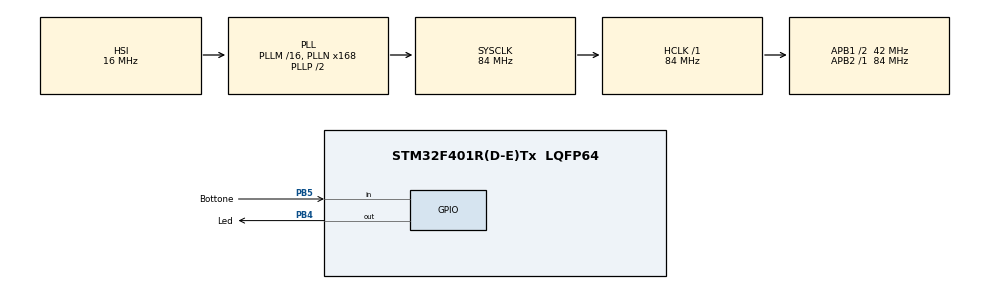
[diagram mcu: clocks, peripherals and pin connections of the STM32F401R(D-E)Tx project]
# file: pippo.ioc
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Mcu.Family=STM32F4
Mcu.Name=STM32F401R(D-E)Tx
Mcu.Package=LQFP64
NVIC.PriorityGroup=NVIC_PRIORITYGROUP_4
PA13.Mode=Serial_Wire
PA13.Signal=SYS_JTMS-SWDIO
PA14.Mode=Serial_Wire
PA14.Signal=SYS_JTCK-SWCLK
PB4.GPIO_Label=Led
PB4.Signal=GPIO_Output
PB5.GPIO_Label=Bottone
PB5.GPIO_PuPd=GPIO_PULLDOWN
PB5.Signal=GPIO_Input
PH0\ -\ OSC_IN.Mode=HSE-External-Oscillator
PH0\ -\ OSC_IN.Signal=RCC_OSC_IN
PH1\ -\ OSC_OUT.Mode=HSE-External-Oscillator
PH1\ -\ OSC_OUT.Signal=RCC_OSC_OUT
ProjectManager.HeapSize=0x200
ProjectManager.StackSize=0x400
ProjectManager.TargetToolchain=MDK-ARM V5.27
RCC.48MHZClocksFreq_Value=42000000
RCC.AHBFreq_Value=84000000
RCC.APB1CLKDivider=RCC_HCLK_DIV2
RCC.APB1Freq_Value=42000000
RCC.APB1TimFreq_Value=84000000
RCC.APB2Freq_Value=84000000
RCC.APB2TimFreq_Value=84000000
RCC.CortexFreq_Value=84000000
RCC.HCLKFreq_Value=84000000
RCC.HSE_VALUE=25000000
RCC.HSI_VALUE=16000000
RCC.LSE_VALUE=32768
RCC.PLLN=168
RCC.SYSCLKFreq_VALUE=84000000
RCC.SYSCLKSource=RCC_SYSCLKSOURCE_PLLCLK
RCC.VCOOutputFreq_Value=168000000
board=custom

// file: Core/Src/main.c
/* USER CODE BEGIN Header */
/**
  ******************************************************************************
  * @file           : main.c
  * @brief          : Main program body
  ******************************************************************************
  * @attention
  *
  * <h2><center>&copy; Copyright (c) 2021 STMicroelectronics.
  * All rights reserved.</center></h2>
  *
  * This software component is licensed by ST under BSD 3-Clause license,
  * the "License"; You may not use this file except in compliance with the
  * License. You may obtain a copy of the License at:
  *                        opensource.org/licenses/BSD-3-Clause
  *
  ******************************************************************************
  */
/* USER CODE END Header */
#include "main.h"

void SystemClock_Config(void);
static void MX_GPIO_Init(void);

int main(void)
{

  /* MCU Configuration--------------------------------------------------------*/

  /* Reset of all peripherals, Initializes the Flash interface and the Systick. */
  HAL_Init();

  /* Configure the system clock */
  SystemClock_Config();

  /* Initialize all configured peripherals */
  MX_GPIO_Init();
  /* USER CODE BEGIN 2 */

	HAL_GPIO_WritePin(Led_GPIO_Port, Led_Pin, GPIO_PIN_RESET);
	Led_GPIO_Port -> ODR &= ~Led_Pin;

	uint8_t stato = 0;

  /* USER CODE END 2 */

  /* Infinite loop */
  /* USER CODE BEGIN WHILE */
  while (1)
  {
		if(HAL_GPIO_ReadPin(Bottone_GPIO_Port, Bottone_Pin)){
				stato = !stato;
				HAL_Delay(250);
		}

	HAL_GPIO_WritePin(Led_GPIO_Port, Led_Pin, stato);
  }
  /* USER CODE END 3 */
}

void SystemClock_Config(void)
{
  RCC_OscInitTypeDef RCC_OscInitStruct = {0};
  RCC_ClkInitTypeDef RCC_ClkInitStruct = {0};

  /** Configure the main internal regulator output voltage
  */
  __HAL_RCC_PWR_CLK_ENABLE();
  __HAL_PWR_VOLTAGESCALING_CONFIG(PWR_REGULATOR_VOLTAGE_SCALE2);
  /** Initializes the RCC Oscillators according to the specified parameters
  * in the RCC_OscInitTypeDef structure.
  */
  RCC_OscInitStruct.OscillatorType = RCC_OSCILLATORTYPE_HSI;
  RCC_OscInitStruct.HSIState = RCC_HSI_ON;
  RCC_OscInitStruct.HSICalibrationValue = RCC_HSICALIBRATION_DEFAULT;
  RCC_OscInitStruct.PLL.PLLState = RCC_PLL_ON;
  RCC_OscInitStruct.PLL.PLLSource = RCC_PLLSOURCE_HSI;
  RCC_OscInitStruct.PLL.PLLM = 16;
  RCC_OscInitStruct.PLL.PLLN = 168;
  RCC_OscInitStruct.PLL.PLLP = RCC_PLLP_DIV2;
  RCC_OscInitStruct.PLL.PLLQ = 4;
  if (HAL_RCC_OscConfig(&RCC_OscInitStruct) != HAL_OK)
  {
    Error_Handler();
  }
  /** Initializes the CPU, AHB and APB buses clocks
  */
  RCC_ClkInitStruct.ClockType = RCC_CLOCKTYPE_HCLK|RCC_CLOCKTYPE_SYSCLK
                              |RCC_CLOCKTYPE_PCLK1|RCC_CLOCKTYPE_PCLK2;
  RCC_ClkInitStruct.SYSCLKSource = RCC_SYSCLKSOURCE_PLLCLK;
  RCC_ClkInitStruct.AHBCLKDivider = RCC_SYSCLK_DIV1;
  RCC_ClkInitStruct.APB1CLKDivider = RCC_HCLK_DIV2;
  RCC_ClkInitStruct.APB2CLKDivider = RCC_HCLK_DIV1;

  if (HAL_RCC_ClockConfig(&RCC_ClkInitStruct, FLASH_LATENCY_2) != HAL_OK)
  {
    Error_Handler();
  }
}

static void MX_GPIO_Init(void)
{
  GPIO_InitTypeDef GPIO_InitStruct = {0};

  /* GPIO Ports Clock Enable */
  __HAL_RCC_GPIOH_CLK_ENABLE();
  __HAL_RCC_GPIOA_CLK_ENABLE();
  __HAL_RCC_GPIOB_CLK_ENABLE();

  /*Configure GPIO pin Output Level */
  HAL_GPIO_WritePin(Led_GPIO_Port, Led_Pin, GPIO_PIN_RESET);

  /*Configure GPIO pin : Led_Pin */
  GPIO_InitStruct.Pin = Led_Pin;
  GPIO_InitStruct.Mode = GPIO_MODE_OUTPUT_PP;
  GPIO_InitStruct.Pull = GPIO_NOPULL;
  GPIO_InitStruct.Speed = GPIO_SPEED_FREQ_LOW;
  HAL_GPIO_Init(Led_GPIO_Port, &GPIO_InitStruct);

  /*Configure GPIO pin : Bottone_Pin */
  GPIO_InitStruct.Pin = Bottone_Pin;
  GPIO_InitStruct.Mode = GPIO_MODE_INPUT;
  GPIO_InitStruct.Pull = GPIO_PULLDOWN;
  HAL_GPIO_Init(Bottone_GPIO_Port, &GPIO_InitStruct);

}

void Error_Handler(void)
{
  __disable_irq();
  while (1)
  {
  }
}

/************************ (C) COPYRIGHT STMicroelectronics *****END OF FILE****/
